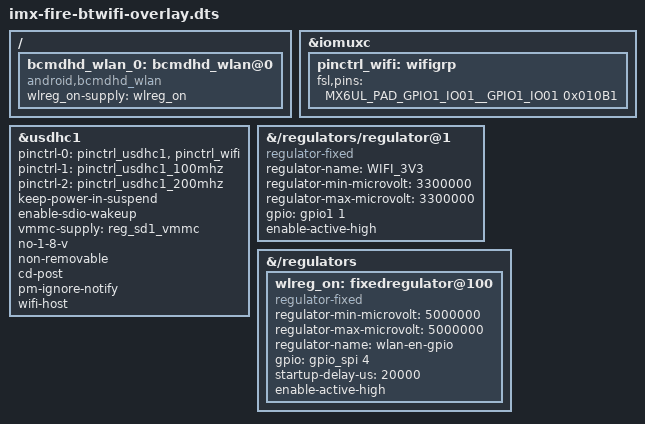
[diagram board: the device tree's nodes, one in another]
/*
 * Copyright (C) 2019 - All Rights Reserved by 
 * filename : imx-fire-key-overlay.dts
 * brief : Device Tree overlay for EBF6ull key device
 * author : embedfire
 * date : 2019-12-10
 * version : A001
 */
#include "../imx6ul-pinfunc.h"
#include "../imx6ull-pinfunc.h"
#include "../imx6ull-pinfunc-snvs.h"
#include "dt-bindings/input/linux-event-codes.h"
#include "dt-bindings/gpio/gpio.h"

/dts-v1/;
/plugin/;

/{
	fragment@0{
		target = <&iomuxc>;
		__overlay__ {	
            pinctrl_wifi: wifigrp {
                fsl,pins = <
                MX6UL_PAD_GPIO1_IO01__GPIO1_IO01 0x010B1
                >;
            };
		};
	};

    fragment@1{
        target-path="/";
        __overlay__{
            bcmdhd_wlan_0: bcmdhd_wlan@0 {
                compatible = "android,bcmdhd_wlan";
                wlreg_on-supply = <&wlreg_on>;
            };

      
        };
    };

    fragment@2{
        target=<&usdhc1>;
        __overlay__{
            pinctrl-names = "default";
            pinctrl-0 = <&pinctrl_usdhc1 &pinctrl_wifi>;
            
            pinctrl-1 = <&pinctrl_usdhc1_100mhz>;
            pinctrl-2 = <&pinctrl_usdhc1_200mhz>;
            /*cd-gpios = <&gpio1 1 GPIO_ACTIVE_LOW>;*/
            keep-power-in-suspend;
            enable-sdio-wakeup;
            vmmc-supply = <&reg_sd1_vmmc>;
            no-1-8-v;
            non-removable;
            cd-post;
            pm-ignore-notify;
            wifi-host;
            status = "okay";
        };
    };

    fragment@3{
            target-path="/regulators/regulator@1";
            __overlay__{
                compatible = "regulator-fixed";
                regulator-name = "WIFI_3V3";
                regulator-min-microvolt = <3300000>;
                regulator-max-microvolt = <3300000>;
                gpio = <&gpio1 1 GPIO_ACTIVE_HIGH>;
                enable-active-high;
            };
    };

    fragment@4{
        target-path="/regulators";
        __overlay__{
            wlreg_on: fixedregulator@100 {
                compatible = "regulator-fixed";
                regulator-min-microvolt = <5000000>;
                regulator-max-microvolt = <5000000>;
                regulator-name = "wlan-en-gpio";
                gpio = <&gpio_spi 4 0>;
                startup-delay-us = <20000>;
                enable-active-high;
            };
        };
    };



};
